# LPC11Exx register map
File version: 5
LPC11Exx 32-bit ARM Cortex-M0 microcontroller; up to 32 kB flash; up to 10 kB SRAM and 4 kB EEPROM; USART
CPU: CM0 r0p0, little endian, no MPU, no FPU, 2 interrupt priority bits
Registers are 32-bit, read-write, reset 0x0 unless marked. A register's access mark holds for its fields unless they carry their own. Offsets are from the block's base; lines under a group give offsets from that group; [hi:lo] are bit positions; {n}, {i} and the like mark numbered series; 'fields as' and 'values as' point back to an identical list; <NAME> marks a mode.

## Memory map
0x40000000 I2C size 0xFFF — I2C-bus controller
0x40004000 WWDT size 0xFFF — Windowed Watchdog Timer (WWDT)
0x40008000 USART size 0xFFF
0x4000C000 CT16B0 size 0xFFF — 16-bit counter/timers CT16B0
0x40010000 CT16B1 size 0xFFF — 16-bit counter/timers CT16B1
0x40014000 CT32B0 size 0xFFF — 32-bit counter/timers CT32B0
0x40018000 CT32B1 size 0xFFF — 32-bit counter/timers CT32B1
0x4001C000 ADC size 0xFFF
0x40038000 PMU size 0xFFF — Power Management Unit (PMU)
0x4003C000 FLASHCTRL size 0xFFF — Flash programming firmware Modification
0x40040000 SSP0 size 0xFFF — SSP/SPI
0x40044000 IOCON size 0xFFF — I/O configuration
0x40048000 SYSCON size 0xFFF — System control block
0x4004C000 GPIO_PIN_INT size 0xFFF — Product name title=UM10462 Chapter title=LPC11U1x GPIO Modification date=3/17/2011 Major revision=0 Minor revision=3
0x40058000 SSP1 size 0xFFF
0x4005C000 GPIO_GROUP_INT0 size 0xFFF — Product name title=UM10462 Chapter title=LPC11U1x GPIO Modification date=3/17/2011 Major revision=0 Minor revision=3
0x40060000 GPIO_GROUP_INT1 size 0xFFF
0x50000000 GPIO_PORT size 0xFFFFF — GPIO Modification

## Interrupts
{n} PIN_INT{n} (GPIO_PIN_INT) (n=0..7)
8 GINT0 (GPIO_GROUP_INT0)
9 GINT1 (GPIO_GROUP_INT1)
14 SSP1
15 I2C
16 CT16B0
17 CT16B1
18 CT32B0
19 CT32B1
20 SSP0
21 USART
24 ADC
25 WDT (WWDT)
27 FLASH_IRQ (FLASHCTRL)

## PMU — Power Management Unit (PMU)
Base 0x40038000
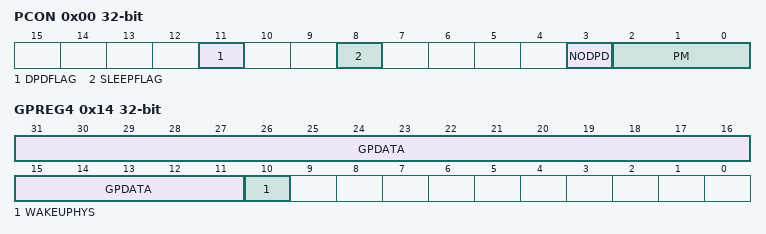
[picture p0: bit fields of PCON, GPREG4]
0x00 PCON — Power control register
  [11] DPDFLAG — Deep power-down flag
    0=DPNOTENTERED (Read: Deep power-down mode not entered. Write: No effect.); 1=DPENTERED (Read: Deep power-down mode entered. Write: Clear the Deep power-down flag.)
  [8] SLEEPFLAG — Sleep mode flag
    0=NOPOWERDOWN (Read: No power-down mode entered. LPC11U1x is in Active mode. Write: No effect.); 1=POWERDOWN (Read: Sleep/Deep-sleep or Deep power-down mode entered. Write: Writing a 1 clears the SLEEPFLAG bit to 0.)
  [3] NODPD — A 1 in this bit prevents entry to Deep power-down mode when 0x3 is written to the PM field above, the SLEEPDEEP bit is set, and a WFI is executed. Execution continues after the WFI if this bit is 1. This bit is cleared only by power-on reset, so writing a one to this bit locks the part in a mode in which Deep power-down mode is blocked.
  [2:0] PM — Power mode
    0=DEFAULT (Default. The part is in active or sleep mode.); 1=DEEPSLEEP (ARM WFI will enter Deep-sleep mode.); 2=POWERDOWN (ARM WFI will enter Power-down mode.); 3=DEEPPOWERDOWN (ARM WFI will enter Deep-power down mode (ARM Cortex-M0 core powered-down).)
{0x4+4i} GPREG{i} (i=0..3) — General purpose register 0
  [31:0] GPDATA — Data retained during Deep power-down mode.
0x14 GPREG4 — General purpose register 4
  [31:11] GPDATA — Data retained during Deep power-down mode.
  [10] WAKEUPHYS — WAKEUP pin hysteresis enable
    0=DISABLED (Hysteresis for WAKEUP pin disabled.); 1=ENABLED (Hysteresis for WAKEUP pin enabled.)

## GPIO_GROUP_INT0 — Product name title=UM10462 Chapter title=LPC11U1x GPIO Modification date=3/17/2011 Major revision=0 Minor revision=3
Base 0x4005C000
Same registers: GPIO_GROUP_INT1 0x40060000
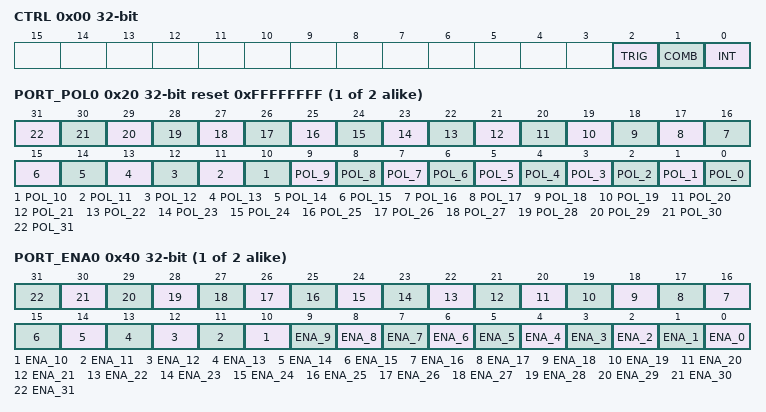
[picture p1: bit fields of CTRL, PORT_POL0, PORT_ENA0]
0x00 CTRL — GPIO grouped interrupt control register
  [2] TRIG — Group interrupt trigger
    0=EDGE_TRIGGERED; 1=LEVEL_TRIGGERED
  [1] COMB — Combine enabled inputs for group interrupt
    0=OR_FUNCTIONALITY_A_ (OR functionality: A grouped interrupt is generated when any one of the enabled inputs is active (based on its programmed polarity).); 1=AND_FUNCTIONALITY_A (AND functionality: An interrupt is generated when all enabled bits are active (based on their programmed polarity).)
  [0] INT — Group interrupt status. This bit is cleared by writing a one to it. Writing zero has no effect.
    0=NO_INTERRUPT_REQUEST (No interrupt request is pending.); 1=INTERRUPT_REQUEST_IS (Interrupt request is active.)
{0x20+4i} PORT_POL{i} (i=0..1) reset 0xFFFFFFFF — GPIO grouped interrupt port 0 polarity register
  [n] POL_{n} (n=1..31) — Configure pin polarity of port 0/1 pins for group interrupt. Bit n corresponds to pin P0/1_n of port 0/1. 0 = the pin is active LOW. If the level on this pin is LOW, the pin contributes to the group interrupt. 1 = the pin is active HIGH. If the level on this pin is HIGH, the pin contributes to the group interrupt.
  [0] POL_0 — Configure pin polarity of port pins for group interrupt. Bit n corresponds to pin P0/1_n of port 0/1 . 0 = the pin is active LOW. If the level on this pin is LOW, the pin contributes to the group interrupt. 1 = the pin is active HIGH. If the level on this pin is HIGH, the pin contributes to the group interrupt.
{0x40+4i} PORT_ENA{i} (i=0..1) — GPIO grouped interrupt port 0/1 enable register
  [n] ENA_{n} (n=0..31) — Enable port 0/1 pin for group interrupt. Bit n corresponds to pin P0/1_n of port 0/1. 0 = the port 0/1 pin is disabled and does not contribute to the grouped interrupt. 1 = the port 0/1 pin is enabled and contributes to the grouped interrupt.
